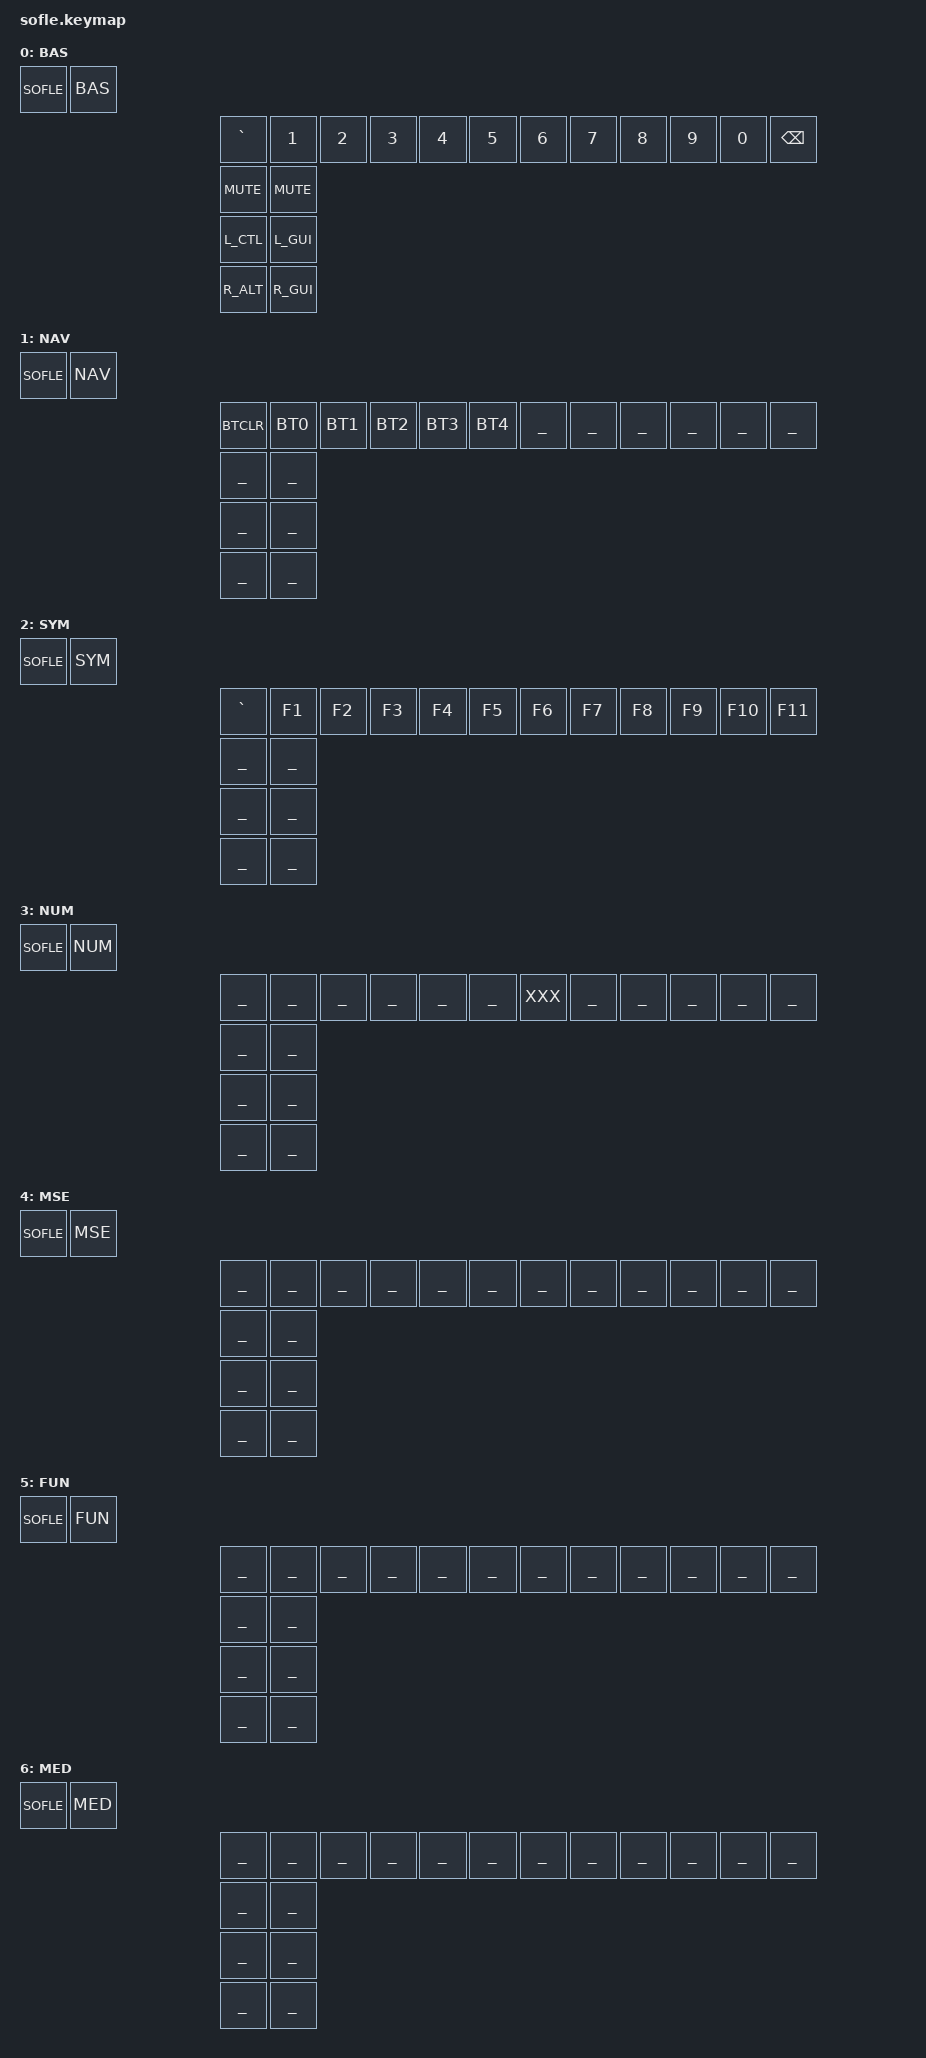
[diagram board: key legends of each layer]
/*
 * Sofle. 공통 42키는 config/keymap_common.dtsi 에서 고친다.
 * 여기는 Sofle에만 있는 키(숫자열, 엔코더 누름, 바깥 엄지 2개씩)만 적는다.
 *
 *   숫자열  [ 12키 ]
 *   공통    [ 6 ][ 6 ]
 *   공통    [ 6 ][ 6 ]
 *   공통    [ 6 ] 엔코더 2 [ 6 ]
 *   왼엄지 2 [ 공통 3 ][ 공통 3 ] 오른엄지 2
 */

#include <dt-bindings/zmk/ext_power.h>

#define LEFT_KEYS    0 1 2 3 4 5  12 13 14 15 16 17  24 25 26 27 28 29  36 37 38 39 40 41 42  50 51 52 53 54
#define RIGHT_KEYS   6 7 8 9 10 11  18 19 20 21 22 23  30 31 32 33 34 35  43 44 45 46 47 48 49  55 56 57 58 59
#define LEFT_THUMBS  50 51 52 53 54
#define RIGHT_THUMBS 55 56 57 58 59

#include "keymap_common.dtsi"

#define SOFLE(...) SOFLE_(__VA_ARGS__)
#define SOFLE_(l0, r0, l1, r1, l2, r2, lt, rt, num, enc, tl, tr) \
    num  l0 r0  l1 r1  l2 enc r2  tl lt rt tr

/ {
    keymap {
        compatible = "zmk,keymap";

        default_layer {
            display-name = "BAS";
            bindings = <SOFLE(BAS,
                /* 숫자열     */ &kp GRAVE  &kp N1  &kp N2  &kp N3  &kp N4  &kp N5  &kp N6  &kp N7  &kp N8  &kp N9  &kp N0  &kp BSPC,
                /* 엔코더     */ MUTE  MUTE,
                /* 왼엄지     */ L_CTL  L_GUI,
                /* 오른엄지   */ R_ALT  R_GUI
            )>;
            sensor-bindings = <&inc_dec_kp C_VOL_DN C_VOL_UP &inc_dec_kp PG_DN PG_UP>;
        };

        nav_layer {
            display-name = "NAV";
            bindings = <SOFLE(NAV,
                /* 숫자열     */ BTCLR  BT0  BT1  BT2  BT3  BT4  ___  ___  ___  ___  ___  ___,
                /* 엔코더     */ ___  ___,
                /* 왼엄지     */ ___  ___,
                /* 오른엄지   */ ___  ___
            )>;
            sensor-bindings = <&inc_dec_kp C_VOL_DN C_VOL_UP &inc_dec_kp PG_DN PG_UP>;
        };

        symbol_layer {
            display-name = "SYM";
            bindings = <SOFLE(SYM,
                /* 숫자열     */ &kp GRAVE  &kp F1  &kp F2  &kp F3  &kp F4  &kp F5  &kp F6  &kp F7  &kp F8  &kp F9  &kp F10  &kp F11,
                /* 엔코더     */ ___  ___,
                /* 왼엄지     */ ___  ___,
                /* 오른엄지   */ ___  ___
            )>;
            sensor-bindings = <&inc_dec_kp C_VOL_DN C_VOL_UP &inc_dec_kp PG_DN PG_UP>;
        };

        number_layer {
            display-name = "NUM";
            bindings = <SOFLE(NUM,
                /* 숫자열     */ ___  ___  ___  ___  ___  ___  XXX  ___  ___  ___  ___  ___,
                /* 엔코더     */ ___  ___,
                /* 왼엄지     */ ___  ___,
                /* 오른엄지   */ ___  ___
            )>;
            sensor-bindings = <&inc_dec_kp C_VOL_DN C_VOL_UP &inc_dec_kp PG_DN PG_UP>;
        };

        mouse_layer {
            display-name = "MSE";
            bindings = <SOFLE(MSE,
                /* 숫자열     */ ___  ___  ___  ___  ___  ___  ___  ___  ___  ___  ___  ___,
                /* 엔코더     */ ___  ___,
                /* 왼엄지     */ ___  ___,
                /* 오른엄지   */ ___  ___
            )>;
            sensor-bindings = <&inc_dec_kp C_VOL_DN C_VOL_UP &inc_dec_kp PG_DN PG_UP>;
        };

        func_layer {
            display-name = "FUN";
            bindings = <SOFLE(FUN,
                /* 숫자열     */ ___  ___  ___  ___  ___  ___  ___  ___  ___  ___  ___  ___,
                /* 엔코더     */ ___  ___,
                /* 왼엄지     */ ___  ___,
                /* 오른엄지   */ ___  ___
            )>;
            sensor-bindings = <&inc_dec_kp C_VOL_DN C_VOL_UP &inc_dec_kp PG_DN PG_UP>;
        };

        media_layer {
            display-name = "MED";
            bindings = <SOFLE(MED,
                /* 숫자열     */ ___  ___  ___  ___  ___  ___  ___  ___  ___  ___  ___  ___,
                /* 엔코더     */ ___  ___,
                /* 왼엄지     */ ___  ___,
                /* 오른엄지   */ ___  ___
            )>;
            sensor-bindings = <&inc_dec_kp C_VOL_DN C_VOL_UP &inc_dec_kp PG_DN PG_UP>;
        };

    };
};
